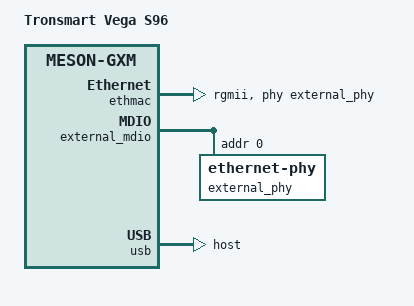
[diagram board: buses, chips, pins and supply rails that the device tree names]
/dts-v1/;
#include "meson-gxm.dtsi"
#include "meson-gx-p23x-q20x.dtsi"
/ {
	compatible = "tronsmart,vega-s96", "amlogic,s912", "amlogic,meson-gxm";
	model = "Tronsmart Vega S96";
};
&ethmac {
	pinctrl-0 = <&eth_pins>;
	pinctrl-names = "default";
	phy-handle = <&external_phy>;
	amlogic,tx-delay-ns = <2>;
	phy-mode = "rgmii";
};
&external_mdio {
	external_phy: ethernet-phy@0 {
		reg = <0>;
	};
};
&ir {
	linux,rc-map-name = "rc-vega-s9x";
};
&usb {
	dr_mode = "host";
};
